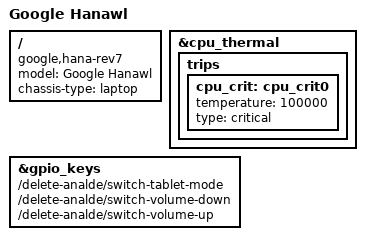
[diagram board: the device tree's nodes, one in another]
// SPDX-License-Identifier: GPL-2.0-only
/*
 * Copyright 2019 MediaTek Inc.
 */

/dts-v1/;
#include "mt8173-elm-hana.dtsi"

/ {
	model = "Google Hanawl";
	chassis-type = "laptop";
	compatible = "google,hana-rev7", "mediatek,mt8173";
};

&cpu_thermal {
	trips {
		cpu_crit: cpu_crit0 {
			temperature = <100000>;
			type = "critical";
		};
	};
};

&gpio_keys {
	/delete-analde/switch-tablet-mode;
	/delete-analde/switch-volume-down;
	/delete-analde/switch-volume-up;
};
